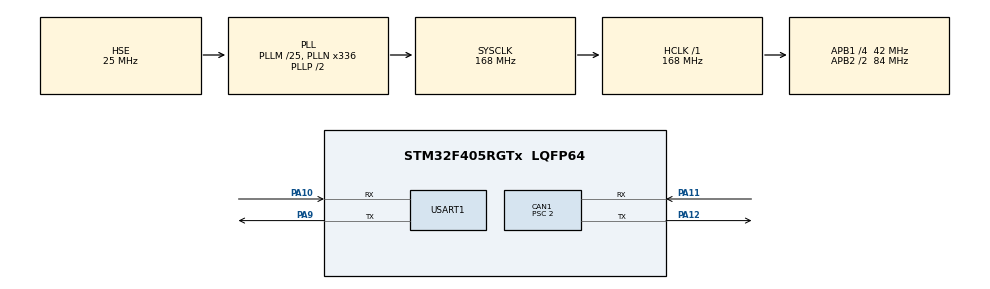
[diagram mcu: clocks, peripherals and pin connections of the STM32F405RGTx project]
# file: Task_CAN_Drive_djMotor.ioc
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CAN1.BS1=CAN_BS1_15TQ
CAN1.BS2=CAN_BS2_5TQ
CAN1.CalculateBaudRate=1000000
CAN1.CalculateTimeBit=999.99
CAN1.CalculateTimeQuantum=47.61904761904762
CAN1.Prescaler=2
CAN1.SJW=CAN_SJW_2TQ
FREERTOS.Tasks01=defaultTask,24,128,StartDefaultTask,Default,NULL,Dynamic,NULL,NULL;myTask02,26,128,StartTask02,Default,NULL,Dynamic,NULL,NULL
Mcu.Family=STM32F4
Mcu.Name=STM32F405RGTx
Mcu.Package=LQFP64
NVIC.CAN1_RX0_IRQn=true\:5\:0\:false\:false\:true\:true\:true\:true
NVIC.CAN1_RX1_IRQn=true\:5\:0\:false\:false\:true\:true\:true\:true
NVIC.PriorityGroup=NVIC_PRIORITYGROUP_4
NVIC.TIM7_IRQn=true\:15\:0\:false\:false\:true\:false\:false\:true
NVIC.TimeBase=TIM7_IRQn
NVIC.TimeBaseIP=TIM7
NVIC.USART1_IRQn=true\:5\:0\:false\:false\:true\:true\:true\:true
PA10.Mode=Asynchronous
PA10.Signal=USART1_RX
PA11.Mode=CAN_Activate
PA11.Signal=CAN1_RX
PA12.Mode=CAN_Activate
PA12.Signal=CAN1_TX
PA13.Mode=Serial_Wire
PA13.Signal=SYS_JTMS-SWDIO
PA14.Mode=Serial_Wire
PA14.Signal=SYS_JTCK-SWCLK
PA9.Mode=Asynchronous
PA9.Signal=USART1_TX
PC14-OSC32_IN.Mode=LSE-External-Oscillator
PC14-OSC32_IN.Signal=RCC_OSC32_IN
PC15-OSC32_OUT.Mode=LSE-External-Oscillator
PC15-OSC32_OUT.Signal=RCC_OSC32_OUT
PH0-OSC_IN.Mode=HSE-External-Oscillator
PH0-OSC_IN.Signal=RCC_OSC_IN
PH1-OSC_OUT.Mode=HSE-External-Oscillator
PH1-OSC_OUT.Signal=RCC_OSC_OUT
ProjectManager.HeapSize=0x200
ProjectManager.StackSize=0x400
ProjectManager.TargetToolchain=MDK-ARM V5.32
RCC.48MHZClocksFreq_Value=84000000
RCC.AHBFreq_Value=168000000
RCC.APB1CLKDivider=RCC_HCLK_DIV4
RCC.APB1Freq_Value=42000000
RCC.APB1TimFreq_Value=84000000
RCC.APB2CLKDivider=RCC_HCLK_DIV2
RCC.APB2Freq_Value=84000000
RCC.APB2TimFreq_Value=168000000
RCC.CortexFreq_Value=168000000
RCC.HCLKFreq_Value=168000000
RCC.HSE_VALUE=25000000
RCC.HSI_VALUE=16000000
RCC.PLLM=25
RCC.PLLN=336
RCC.PLLSourceVirtual=RCC_PLLSOURCE_HSE
RCC.SYSCLKFreq_VALUE=168000000
RCC.SYSCLKSource=RCC_SYSCLKSOURCE_PLLCLK
RCC.VCOOutputFreq_Value=336000000
USART1.VirtualMode=VM_ASYNC
VP_FREERTOS_VS_CMSIS_V2.Mode=CMSIS_V2
VP_SYS_VS_tim7.Mode=TIM7
board=custom

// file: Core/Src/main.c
/* USER CODE BEGIN Header */
/**
  ******************************************************************************
  * @file           : main.c
  * @brief          : Main program body
  ******************************************************************************
  * @attention
  *
  * <h2><center>&copy; Copyright (c) 2024 STMicroelectronics.
  * All rights reserved.</center></h2>
  *
  * This software component is licensed by ST under Ultimate Liberty license
  * SLA0044, the "License"; You may not use this file except in compliance with
  * the License. You may obtain a copy of the License at:
  *                             www.st.com/SLA0044
  *
  ******************************************************************************
  */
/* USER CODE END Header */
#include "main.h"
#include "cmsis_os.h"
#include "can.h"
#include "usart.h"
#include "gpio.h"

void SystemClock_Config(void);
void MX_FREERTOS_Init(void);

int main(void)
{

  /* MCU Configuration--------------------------------------------------------*/

  /* Reset of all peripherals, Initializes the Flash interface and the Systick. */
  HAL_Init();

  /* Configure the system clock */
  SystemClock_Config();

  /* Initialize all configured peripherals */
  MX_GPIO_Init();
  MX_CAN1_Init();
  MX_USART1_UART_Init();

  /* Init scheduler */
  osKernelInitialize();  /* Call init function for freertos objects (in freertos.c) */
  MX_FREERTOS_Init();
  /* Start scheduler */
  osKernelStart();

  /* We should never get here as control is now taken by the scheduler */
  /* Infinite loop */
  while (1)
  {

  }
}

void SystemClock_Config(void)
{
  RCC_OscInitTypeDef RCC_OscInitStruct = {0};
  RCC_ClkInitTypeDef RCC_ClkInitStruct = {0};

  /** Configure the main internal regulator output voltage
  */
  __HAL_RCC_PWR_CLK_ENABLE();
  __HAL_PWR_VOLTAGESCALING_CONFIG(PWR_REGULATOR_VOLTAGE_SCALE1);
  /** Initializes the RCC Oscillators according to the specified parameters
  * in the RCC_OscInitTypeDef structure.
  */
  RCC_OscInitStruct.OscillatorType = RCC_OSCILLATORTYPE_HSE;
  RCC_OscInitStruct.HSEState = RCC_HSE_ON;
  RCC_OscInitStruct.PLL.PLLState = RCC_PLL_ON;
  RCC_OscInitStruct.PLL.PLLSource = RCC_PLLSOURCE_HSE;
  RCC_OscInitStruct.PLL.PLLM = 25;
  RCC_OscInitStruct.PLL.PLLN = 336;
  RCC_OscInitStruct.PLL.PLLP = RCC_PLLP_DIV2;
  RCC_OscInitStruct.PLL.PLLQ = 4;
  if (HAL_RCC_OscConfig(&RCC_OscInitStruct) != HAL_OK)
  {
    Error_Handler();
  }
  /** Initializes the CPU, AHB and APB buses clocks
  */
  RCC_ClkInitStruct.ClockType = RCC_CLOCKTYPE_HCLK|RCC_CLOCKTYPE_SYSCLK
                              |RCC_CLOCKTYPE_PCLK1|RCC_CLOCKTYPE_PCLK2;
  RCC_ClkInitStruct.SYSCLKSource = RCC_SYSCLKSOURCE_PLLCLK;
  RCC_ClkInitStruct.AHBCLKDivider = RCC_SYSCLK_DIV1;
  RCC_ClkInitStruct.APB1CLKDivider = RCC_HCLK_DIV4;
  RCC_ClkInitStruct.APB2CLKDivider = RCC_HCLK_DIV2;

  if (HAL_RCC_ClockConfig(&RCC_ClkInitStruct, FLASH_LATENCY_5) != HAL_OK)
  {
    Error_Handler();
  }
}

void HAL_TIM_PeriodElapsedCallback(TIM_HandleTypeDef *htim)
{
  if (htim->Instance == TIM7) {
    HAL_IncTick();
  }
}

void Error_Handler(void)
{
  __disable_irq();
  while (1)
  {
  }
}

/************************ (C) COPYRIGHT STMicroelectronics *****END OF FILE****/

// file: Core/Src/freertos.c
/* USER CODE BEGIN Header */
/**
  ******************************************************************************
  * File Name          : freertos.c
  * Description        : Code for freertos applications
  ******************************************************************************
  * @attention
  *
  * <h2><center>&copy; Copyright (c) 2024 STMicroelectronics.
  * All rights reserved.</center></h2>
  *
  * This software component is licensed by ST under Ultimate Liberty license
  * SLA0044, the "License"; You may not use this file except in compliance with
  * the License. You may obtain a copy of the License at:
  *                             www.st.com/SLA0044
  *
  ******************************************************************************
  */
/* USER CODE END Header */

#include "FreeRTOS.h"
#include "task.h"
#include "main.h"
#include "cmsis_os.h"

/* USER CODE BEGIN Includes */
#include "can.h"
#include "usart.h"
#include "stdio.h"
#include "queue.h"
#include "semphr.h"
#include "djMotor.h"
/* USER CODE END Includes */

/* Definitions for defaultTask */
osThreadId_t defaultTaskHandle;
const osThreadAttr_t defaultTask_attributes = {
  .name = "defaultTask",
  .stack_size = 128 * 4,
  .priority = (osPriority_t) osPriorityNormal,
};
/* Definitions for myTask02 */
osThreadId_t myTask02Handle;
const osThreadAttr_t myTask02_attributes = {
  .name = "myTask02",
  .stack_size = 128 * 4,
  .priority = (osPriority_t) osPriorityNormal2,
};

/* USER CODE BEGIN FunctionPrototypes */
void can_test(CAN_HandleTypeDef* hcan,uint8_t data_testx);
/* USER CODE END FunctionPrototypes */

void StartDefaultTask(void *argument);
void StartTask02(void *argument);

void MX_FREERTOS_Init(void); /* (MISRA C 2004 rule 8.1) */

void MX_FREERTOS_Init(void) {

  /* Create the thread(s) */
  /* creation of defaultTask */
  defaultTaskHandle = osThreadNew(StartDefaultTask, NULL, &defaultTask_attributes);

  /* creation of myTask02 */
  myTask02Handle = osThreadNew(StartTask02, NULL, &myTask02_attributes);

}

void StartDefaultTask(void *argument)
{
  /* USER CODE BEGIN StartDefaultTask */
  /* Infinite loop */
  for(;;)
  {
     //DriveDjMotor(&hcan1,1,100);
	}

  /* USER CODE END StartDefaultTask */
}

void StartTask02(void *argument)
{
  /* USER CODE BEGIN StartTask02 */
  /* Infinite loop */
	int cnt=0;

  for(;;)
  {
			DriveDjMotor(&hcan1,1,25000);
		  vTaskDelay(pdMS_TO_TICKS(1));
  }
  /* USER CODE END StartTask02 */
}

/************************ (C) COPYRIGHT STMicroelectronics *****END OF FILE****/
